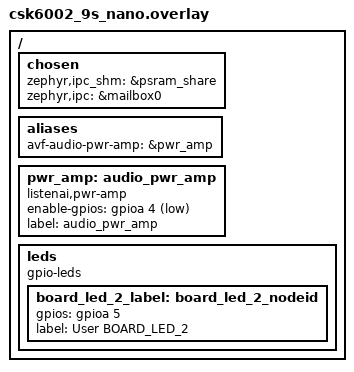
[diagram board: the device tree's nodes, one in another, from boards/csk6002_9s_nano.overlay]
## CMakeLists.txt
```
# SPDX-License-Identifier: Apache-2.0

cmake_minimum_required(VERSION 3.20.0)

set(SUPPORT_BOARDS csk6012_nano csk6011a_nano)
if(NOT ${BOARD} IN_LIST SUPPORT_BOARDS)
    message("Please choose one of the following boards:")
    foreach(item ${SUPPORT_BOARDS})
        message(STATUS ${item})
    endforeach()
    message(FATAL_ERROR "\nThe project does not support the ${BOARD}")
endif()

set(CONF_FILE
  prj.conf
)

if(EXISTS "${CMAKE_CURRENT_SOURCE_DIR}/boards/${BOARD}.conf")
  list(APPEND CONF_FILE
    ${CMAKE_CURRENT_SOURCE_DIR}/boards/${BOARD}.conf
  )
endif()

if(EXISTS "${CMAKE_CURRENT_SOURCE_DIR}/resource/res.conf")
  list(APPEND CONF_FILE
    ${CMAKE_CURRENT_SOURCE_DIR}/resource/res.conf
  )
endif()

set(DTC_OVERLAY_FILE)

if(EXISTS "${CMAKE_CURRENT_SOURCE_DIR}/boards/${BOARD}.overlay")
  list(APPEND DTC_OVERLAY_FILE
    ${CMAKE_CURRENT_SOURCE_DIR}/boards/${BOARD}.overlay
  )
endif()

if(EXISTS "${CMAKE_CURRENT_SOURCE_DIR}/resource/res.overlay")
  list(APPEND DTC_OVERLAY_FILE
    ${CMAKE_CURRENT_SOURCE_DIR}/resource/res.overlay
  )
endif()

find_package(Zephyr REQUIRED HINTS $ENV{ZEPHYR_BASE})
project(sample_aplay)
target_sources(app PRIVATE src/main.c)
```

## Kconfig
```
# SPDX-License-Identifier: Apache-2.0

DT_CHOSEN_Z_IPC_SHM := zephyr,ipc_shm

#SOF IPC MEMORY CONFIG
config AVF_IPC_SHM_BASE_ADDRESS
	default "$(dt_chosen_reg_addr_hex,$(DT_CHOSEN_Z_IPC_SHM))"

config AVF_IPC_SHM_SIZE
	default "$(dt_chosen_reg_size_hex,$(DT_CHOSEN_Z_IPC_SHM))"
	help
	  This option specifies size of the memory region to be used
	  for the SOF IPC shared memory

source "Kconfig.zephyr"
```

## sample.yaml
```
tests:
  sample.board.csk6.subsys.avf.audio.record_play:
    platform_allow: csk6011a_nano
    skip: true
    tags: csk6
    timeout: 20
    harness: console
    harness_config:
      type: multi_line
      regex:
      - "audio play complete.(.*)"
```

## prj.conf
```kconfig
CONFIG_PRINTK=y
CONFIG_DEBUG=y
CONFIG_LOG=y
CONFIG_LOG_MODE_IMMEDIATE=y
CONFIG_LOG_DETECT_MISSED_STRDUP=n
CONFIG_LOG_BACKEND_SHOW_COLOR=y
CONFIG_LOG_BACKEND_FORMAT_TIMESTAMP=y
CONFIG_LOG_BACKEND_UART=y
CONFIG_LOG_BACKEND_UART_OUTPUT_TEXT=y
CONFIG_MAIN_STACK_SIZE=2048
#system heap size,users can define it according to the actual usage
CONFIG_HEAP_MEM_POOL_SIZE=280000
#avf
CONFIG_AVF=y
CONFIG_AVF_DEBUG_LEVEL=1
CONFIG_AVF_USE_BINARY_ARRAY=y

#licak
CONFIG_LICAK=y
CONFIG_LICAK_MODULES_AUDIO_PLAYBACK=y
CONFIG_LICAK_MODULES_AUDIO_CAPTURE=y
CONFIG_LICAK_DISABLE_MULTI_HEAP_INIT=y

#IPM and GPIO for avf driver
CONFIG_IPM=y
#cache
CONFIG_CACHE_MANAGEMENT=y
#psram init for avf ipc share memory
CONFIG_CSK6_PSRAM=y
CONFIG_NEWLIB_LIBC=y
#IPM and GPIO for avf driver
CONFIG_GPIO=y
```

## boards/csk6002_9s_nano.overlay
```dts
/*
 * Copyright (c) 2021 listenai Intelligent Technology (anhui) Co., Ltd.
 *
 * SPDX-License-Identifier: Apache-2.0
 */
 / {
	 chosen {
		 /*
		  * shared memory reserved for the inter-processor communication
		  */
		 zephyr,ipc_shm = &psram_share;
		 zephyr,ipc = &mailbox0;
	 };
 
	 aliases {
		 avf-audio-pwr-amp = &pwr_amp;
	 };
	 pwr_amp:audio_pwr_amp{
		 compatible = "listenai,pwr-amp";
		 enable-gpios = <&gpioa 4 1>;
		 label = "audio_pwr_amp";	
		 status = "okay";
	 };

    leds {
            compatible = "gpio-leds";
            board_led_2_label: board_led_2_nodeid {
                    gpios = <&gpioa 5 0>;
                    label = "User BOARD_LED_2";
            };
    };

 };
 
```

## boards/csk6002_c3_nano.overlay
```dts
/*
 * Copyright (c) 2021 listenai Intelligent Technology (anhui) Co., Ltd.
 *
 * SPDX-License-Identifier: Apache-2.0
 */
 / {
	 chosen {
		 /*
		  * shared memory reserved for the inter-processor communication
		  */
		 zephyr,ipc_shm = &psram_share;
		 zephyr,ipc = &mailbox0;
	 };
 
	 aliases {
		 avf-audio-pwr-amp = &pwr_amp;
	 };
	 pwr_amp:audio_pwr_amp{
		 compatible = "listenai,pwr-amp";
		 enable-gpios = <&gpioa 4 1>;
		 label = "audio_pwr_amp";	
		 status = "okay";
	 };

    leds {
            compatible = "gpio-leds";
            board_led_2_label: board_led_2_nodeid {
                    gpios = <&gpioa 5 0>;
                    label = "User BOARD_LED_2";
            };
    };

 };
 
```

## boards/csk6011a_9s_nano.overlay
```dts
/*
 * Copyright (c) 2021 listenai Intelligent Technology (anhui) Co., Ltd.
 *
 * SPDX-License-Identifier: Apache-2.0
 */
 / {
	 chosen {
		 /*
		  * shared memory reserved for the inter-processor communication
		  */
		 zephyr,ipc_shm = &psram_share;
		 zephyr,ipc = &mailbox0;
	 };
 
	 aliases {
		 avf-audio-pwr-amp = &pwr_amp;
	 };
	 pwr_amp:audio_pwr_amp{
		 compatible = "listenai,pwr-amp";
		 enable-gpios = <&gpioa 4 1>;
		 label = "audio_pwr_amp";	
		 status = "okay";
	 };

    leds {
            compatible = "gpio-leds";
            board_led_2_label: board_led_2_nodeid {
                    gpios = <&gpiob 6 0>;
                    label = "User BOARD_LED_2";
            };
    };

 };
 
```

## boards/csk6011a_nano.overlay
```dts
/*
 * Copyright (c) 2023 Anhui(Shenzhen) Listenai Co., Ltd.
 *
 * SPDX-License-Identifier: Apache-2.0
 */
/ {
	chosen {
		/*
		 * shared memory reserved for the inter-processor communication
		 */
		zephyr,ipc_shm = &psram_share;
		zephyr,ipc = &mailbox0;
	};

	aliases {
		avf-audio-pwr-amp = &pwr_amp;
	};
	pwr_amp: audio_pwr_amp{
		compatible = "listenai,pwr-amp";
		enable-gpios = <&gpioa 4 1>;
		label = "audio_pwr_amp";
		status = "okay";
	};
};
```

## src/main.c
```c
/*
 * Copyright (c) 2023 Anhui(Shenzhen) Listenai Co., Ltd.
 *
 * SPDX-License-Identifier: Apache-2.0
 */
#include "pwr_amp.c"
#include <avf/framework/avf_platform.h>
#include <avf/slogger.h>
#include <device.h>
#include <devicetree.h>
#include <drivers/gpio.h>
#include <licak/licak.h>
#include <licak/modules/audio/acapture.h>
#include <licak/modules/audio/aplay.h>
#include <zephyr.h>

#define ACAPTURE_DATA_EVENT_THRES  (1024)
#define ACAPTURE_DATA_TOTAL_LENGTH (1024 * 100)
#define ACAPTURE_MSGQ_NUMBER	   (50)
typedef struct {
	char *pdata;
	int datalen;
} msgq_data_t;

struct k_msgq acapture_msgq;

static void acapture_data_process(void *priv, acapture_event_msg_t msg)
{
	acapture_t *handle = (acapture_t *)priv;
	msgq_data_t msgq_data;

	uint32_t avail;
	int32_t readlen;
	int ret = 0;

	if (msg.event_flags & AVF_STREAM_EVENT_THRES_NOTIFY) {
		avail = msg.value.value;
		msgq_data.pdata = k_malloc(sizeof(char) * avail);
		if (msgq_data.pdata == NULL) {
			printk("[%s %d]k_malloc FAILED!", __FUNCTION__, __LINE__);
			return;
		}
		readlen = acap_get_datai(handle, msgq_data.pdata, avail);
		if (readlen > 0) {
			msgq_data.datalen = readlen;
			ret = k_msgq_put(&acapture_msgq, &msgq_data, K_NO_WAIT);
			if (ret) {
				k_free(msgq_data.pdata);
				printk("[%s %d]msgq message dropped", __FUNCTION__, __LINE__);
			}
		} else {
			k_free(msgq_data.pdata);
		}
	}
}

void main(void)
{
	/* start record */
	acapture_t *acapture = NULL;
	amedia_fmt_t fmt = {
		.rate = 16000,
		.channels = 1,
		.bits = 16,
		.compr = AMEDIA_COMPR_PCM,
	};

	int iret = 0;
	static char buffer[sizeof(msgq_data_t) * ACAPTURE_MSGQ_NUMBER];
	msgq_data_t msgq_data;

	licak_init();

	k_msgq_init(&acapture_msgq, buffer, sizeof(msgq_data_t), ACAPTURE_MSGQ_NUMBER);

	/*step1: create acapture instance*/
	acapture = acap_create();
	if (acapture == NULL) {
		printk("acap_create failed!\n");
		return;
	}
	printk("Create acapture success\n");

	/*step2: set callback function*/
	if (0 != (iret = acap_event_register(acapture, AVF_STREAM_EVENT_THRES_NOTIFY,
					     acapture_data_process, acapture,
					     ACAPTURE_DATA_EVENT_THRES))) {
		printk("Register data event callback failed, iret %d\n", iret);
		return;
	}
	printk("Register data event callback success.\n");

	/*step3: set acapture paramter*/
	if (0 != (iret = acap_set_fmt(acapture, &fmt))) {
		printk("acap_set_fmt failed!\n");
		return;
	}
	printk("Set audio fmt<%d %d %d> to acapture success\n", fmt.rate, fmt.channels, fmt.bits);

	/*step4: start capture*/
	if (0 != (iret = acap_start(acapture))) {
		printk("acap_start failed.\n");
		return;
	}
	printk("Trigger capture start success.\n");

	/*step5: waiting to revice 5S audio data */
	printk("record start\n");
	k_msleep(5000);

	/*step6: stop acapture*/
	acap_stop(acapture);

	/*step7: destroy aplayer*/
	if (0 != (iret = acap_destroy(acapture))) {
		printk("aplay_destroy failed.\n");
	}

	k_msleep(1000);

	/* start play */
	aplay_t *aplay = NULL;

	/*step1: create aplyer instance*/
	aplay = aplay_create(APLAYER_SUBSTREAM_MAIN);
	if (aplay == NULL) {
		printk("acap_create failed!\n");
		return;
	}
	printk("Create aplay success\n");

	/*step2: set aplayer paramter*/
	if (0 != (iret = aplay_set_fmt(aplay, &fmt))) {
		printk("aplay_set_fmt failed!\n");
		return;
	}
	printk("Set audio fmt to aplay success\n");

	/*Enable audio power-amp*/
	audio_pwr_amp_init();
	audio_pwr_amp_enbale();

	/*step3: start play*/
	if (0 != (iret = aplay_start(aplay))) {
		printk("aplay_set_fmt failed.\n");
		return;
	}
	printk("Trigger play start success.\n");

	/*clear message queue*/
	for (;;) {
		if (0 != k_msgq_get(&acapture_msgq, &msgq_data, K_NO_WAIT)) {
			break;
		}
		/*step4: write data to aplayer*/
		iret = aplay_writei(aplay, msgq_data.pdata, msgq_data.datalen);
		if (iret != msgq_data.datalen) {
			printk("aplay_writei failed ret %d.\n", iret);
		}

		k_free(msgq_data.pdata);
	}

	/*step5: drain or stop aplayer*/
	if (0 != (iret = aplay_drain(aplay))) {
		printk("aplay_drain failed.\n");
		return;
	}
	printk("play drain finsh with timestamp %lld ms\n", k_uptime_get());

	/*step6: destroy aplayer*/
	if (0 != (iret = aplay_destroy(aplay))) {
		printk("aplay_destroy failed.\n");
		return;
	}
	printk("audio play complete. \n");
}
```

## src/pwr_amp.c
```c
/*
 * Copyright (c) 2023 Anhui(Shenzhen) Listenai Co., Ltd.
 *
 * SPDX-License-Identifier: Apache-2.0
 */
#include <device.h>
#include <drivers/gpio.h>
#include <zephyr.h>

#if defined(__ZEPHYR__) && (DT_NODE_HAS_STATUS(DT_ALIAS(avf_audio_pwr_amp), okay))

#define AVF_AUDIO_PWR_AMP	DT_GPIO_LABEL(DT_ALIAS(avf_audio_pwr_amp), enable_gpios)
#define AVF_AUDIO_PWR_AMP_PIN	DT_GPIO_PIN(DT_ALIAS(avf_audio_pwr_amp), enable_gpios)
#define AVF_AUDIO_PWR_AMP_FLAGS DT_GPIO_FLAGS(DT_ALIAS(avf_audio_pwr_amp), enable_gpios)

static inline void audio_pwr_amp_enbale(void)
{

	const struct device *dev;

	dev = device_get_binding(AVF_AUDIO_PWR_AMP);
	if (dev == NULL) {
		return;
	}
	gpio_pin_set(dev, AVF_AUDIO_PWR_AMP_PIN, 1);
}

static inline void audio_pwr_amp_disable(void)
{

	const struct device *dev;

	dev = device_get_binding(AVF_AUDIO_PWR_AMP);
	if (dev == NULL) {
		return;
	}
	gpio_pin_set(dev, AVF_AUDIO_PWR_AMP_PIN, 0);
}

static inline void audio_pwr_amp_init(void)
{
	int ret;
	const struct device *dev;

	dev = device_get_binding(AVF_AUDIO_PWR_AMP);
	if (dev == NULL) {
		return;
	}

	ret = gpio_pin_configure(dev, AVF_AUDIO_PWR_AMP_PIN, GPIO_OUTPUT_ACTIVE);
	if (ret < 0) {
		return;
	}
}

#else
#warning "The amplifier pins are not defined"

static inline void audio_pwr_amp_enbale(void)
{
}
static inline void audio_pwr_amp_disable(void)
{
}
static inline void audio_pwr_amp_init(void)
{
}

#endif
```
